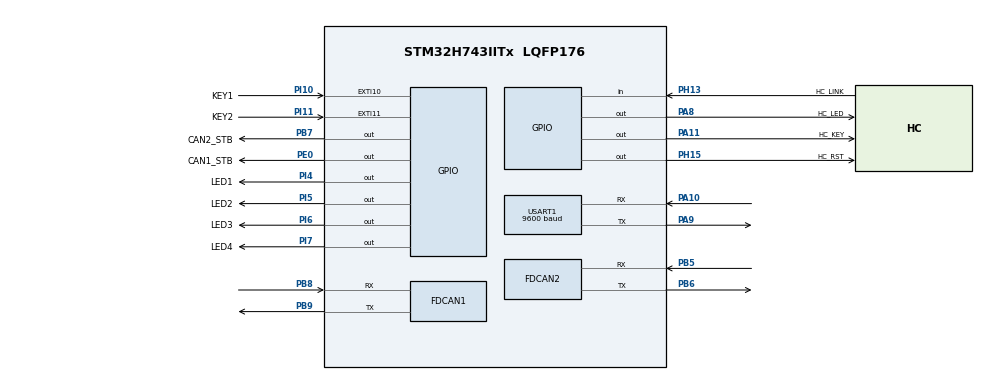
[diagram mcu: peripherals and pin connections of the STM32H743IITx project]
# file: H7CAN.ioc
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FDCAN1.DataSyncJumpWidth=8
FDCAN1.DataTimeSeg1=31
FDCAN1.DataTimeSeg2=8
FDCAN1.NominalSyncJumpWidth=8
FDCAN1.NominalTimeSeg1=31
FDCAN1.NominalTimeSeg2=8
FDCAN2.DataSyncJumpWidth=8
FDCAN2.DataTimeSeg1=31
FDCAN2.DataTimeSeg2=8
FDCAN2.FrameFormat=FDCAN_FRAME_CLASSIC
FDCAN2.NominalPrescaler=1
FDCAN2.NominalSyncJumpWidth=8
FDCAN2.NominalTimeSeg1=31
FDCAN2.NominalTimeSeg2=8
FDCAN2.ProtocolException=ENABLE
FDCAN2.RxBufferSize=FDCAN_DATA_BYTES_8
FDCAN2.RxFifo0ElmtSize=FDCAN_DATA_BYTES_8
FDCAN2.RxFifo0ElmtsNbr=2
FDCAN2.RxFifo1ElmtSize=FDCAN_DATA_BYTES_8
FDCAN2.StdFiltersNbr=1
FDCAN2.TxElmtSize=FDCAN_DATA_BYTES_8
FDCAN2.TxFifoQueueElmtsNbr=1
Mcu.Family=STM32H7
Mcu.Name=STM32H743IITx
Mcu.Package=LQFP176
NVIC.EXTI15_10_IRQn=true\:0\:0\:false\:false\:true\:true\:true
NVIC.PriorityGroup=NVIC_PRIORITYGROUP_4
NVIC.TIM1_UP_IRQn=true\:0\:0\:false\:false\:true\:true\:true
NVIC.USART1_IRQn=true\:0\:0\:false\:false\:true\:true\:true
PA10.GPIO_Speed=GPIO_SPEED_FREQ_VERY_HIGH
PA10.Mode=Asynchronous
PA10.Signal=USART1_RX
PA11.GPIO_Label=HC_KEY
PA11.Signal=GPIO_Output
PA8.GPIO_Label=HC_LED
PA8.Signal=GPIO_Output
PA9.GPIO_Speed=GPIO_SPEED_FREQ_VERY_HIGH
PA9.Mode=Asynchronous
PA9.Signal=USART1_TX
PB5.GPIO_Speed=GPIO_SPEED_FREQ_VERY_HIGH
PB5.Mode=FDCANSlave
PB5.Signal=FDCAN2_RX
PB6.GPIO_FM6=SYSCFG_PMCR_I2C_PB6_FMP
PB6.GPIO_Speed=GPIO_SPEED_FREQ_VERY_HIGH
PB6.Mode=FDCANSlave
PB6.Signal=FDCAN2_TX
PB7.GPIO_Label=CAN2_STB
PB7.GPIO_PuPd=GPIO_PULLDOWN
PB7.Signal=GPIO_Output
PB8.GPIO_FM8=SYSCFG_PMCR_I2C_PB8_FMP
PB8.GPIO_Speed=GPIO_SPEED_FREQ_VERY_HIGH
PB8.Mode=FDCANMaster
PB8.Signal=FDCAN1_RX
PB9.GPIO_FM9=SYSCFG_PMCR_I2C_PB9_FMP
PB9.GPIO_Speed=GPIO_SPEED_FREQ_VERY_HIGH
PB9.Mode=FDCANMaster
PB9.Signal=FDCAN1_TX
PE0.GPIO_Label=CAN1_STB
PE0.Signal=GPIO_Output
PH0-OSC_IN\ (PH0).Mode=HSE-External-Oscillator
PH0-OSC_IN\ (PH0).Signal=RCC_OSC_IN
PH1-OSC_OUT\ (PH1).Mode=HSE-External-Oscillator
PH1-OSC_OUT\ (PH1).Signal=RCC_OSC_OUT
PH13.GPIO_Label=HC_LINK
PH13.Signal=GPIO_Input
PH15.GPIO_Label=HC_RST
PH15.Signal=GPIO_Output
PI10.GPIO_Label=KEY1
PI10.GPIO_PuPd=GPIO_PULLUP
PI10.Signal=GPXTI10
PI11.GPIO_Label=KEY2
PI11.GPIO_PuPd=GPIO_PULLUP
PI11.Signal=GPXTI11
PI4.GPIO_Label=LED1
PI4.Signal=GPIO_Output
PI5.GPIO_Label=LED2
PI5.Signal=GPIO_Output
PI6.GPIO_Label=LED3
PI6.Signal=GPIO_Output
PI7.GPIO_Label=LED4
PI7.Signal=GPIO_Output
ProjectManager.HeapSize=0x200
ProjectManager.StackSize=0x400
ProjectManager.TargetToolchain=MDK-ARM V5
RCC.ADCFreq_Value=50390625
RCC.APB1Freq_Value=50000000
RCC.APB2Freq_Value=50000000
RCC.APB3Freq_Value=50000000
RCC.APB4Freq_Value=50000000
RCC.CortexFreq_Value=200000000
RCC.D1PPRE=RCC_APB3_DIV2
RCC.D2PPRE1=RCC_APB1_DIV2
RCC.D2PPRE2=RCC_APB2_DIV2
RCC.D3PPRE=RCC_APB4_DIV2
RCC.DIVM1=8
RCC.DIVN1=128
RCC.DIVQ1=20
RCC.HCLKFreq_Value=100000000
RCC.HPRE=RCC_HCLK_DIV2
RCC.PLL2FRACN=0
RCC.PLL3FRACN=0
RCC.PLLFRACN=0
RCC.PLLSourceVirtual=RCC_PLLSOURCE_HSE
RCC.SYSCLKFreq_VALUE=200000000
RCC.SYSCLKSource=RCC_SYSCLKSOURCE_PLLCLK
RCC.USBFreq_Value=20000000
TIM1.Period=1000-1
TIM1.Prescaler=19999
USART1.BaudRate=9600
USART1.VirtualMode-Asynchronous=VM_ASYNC
VP_TIM1_VS_ClockSourceINT.Mode=Internal
board=custom

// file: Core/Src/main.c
/* USER CODE BEGIN Header */
/**
  ******************************************************************************
  * @file           : main.c
  * @brief          : Main program body
  ******************************************************************************
  * @attention
  *
  * <h2><center>&copy; Copyright (c) 2019 STMicroelectronics.
  * All rights reserved.</center></h2>
  *
  * This software component is licensed by ST under BSD 3-Clause license,
  * the "License"; You may not use this file except in compliance with the
  * License. You may obtain a copy of the License at:
  *                        opensource.org/licenses/BSD-3-Clause
  *
  ******************************************************************************
  */
/* USER CODE END Header */

#include "main.h"
#include "fdcan.h"
#include "tim.h"
#include "usart.h"
#include "gpio.h"

/* USER CODE BEGIN Includes */
#include "interface.h"
/* USER CODE END Includes */

void SystemClock_Config(void);

int main(void)
{

  /* MCU Configuration--------------------------------------------------------*/

  /* Reset of all peripherals, Initializes the Flash interface and the Systick. */
  HAL_Init();

  /* Configure the system clock */
  SystemClock_Config();

  /* Initialize all configured peripherals */
  MX_GPIO_Init();
  MX_FDCAN2_Init();
  MX_TIM1_Init();
  MX_FDCAN1_Init();
  MX_USART1_UART_Init();
  /* USER CODE BEGIN 2 */

	HardwareInit();
  /* USER CODE END 2 */

  /* Infinite loop */
  /* USER CODE BEGIN WHILE */
  while (1)
  {
		HAL_Delay(300);
		if (PresCANRecvFlg==1)
		{
			BLESend(AllTireInfo);
		}

    /* USER CODE END WHILE */

  }
}

void SystemClock_Config(void)
{
  RCC_OscInitTypeDef RCC_OscInitStruct = {0};
  RCC_ClkInitTypeDef RCC_ClkInitStruct = {0};
  RCC_PeriphCLKInitTypeDef PeriphClkInitStruct = {0};

  /** Supply configuration update enable
  */
  HAL_PWREx_ConfigSupply(PWR_LDO_SUPPLY);
  /** Configure the main internal regulator output voltage
  */
  __HAL_PWR_VOLTAGESCALING_CONFIG(PWR_REGULATOR_VOLTAGE_SCALE3);

  while(!__HAL_PWR_GET_FLAG(PWR_FLAG_VOSRDY)) {}
  /** Initializes the CPU, AHB and APB busses clocks
  */
  RCC_OscInitStruct.OscillatorType = RCC_OSCILLATORTYPE_HSE;
  RCC_OscInitStruct.HSEState = RCC_HSE_ON;
  RCC_OscInitStruct.PLL.PLLState = RCC_PLL_ON;
  RCC_OscInitStruct.PLL.PLLSource = RCC_PLLSOURCE_HSE;
  RCC_OscInitStruct.PLL.PLLM = 8;
  RCC_OscInitStruct.PLL.PLLN = 128;
  RCC_OscInitStruct.PLL.PLLP = 2;
  RCC_OscInitStruct.PLL.PLLQ = 20;
  RCC_OscInitStruct.PLL.PLLR = 2;
  RCC_OscInitStruct.PLL.PLLRGE = RCC_PLL1VCIRANGE_1;
  RCC_OscInitStruct.PLL.PLLVCOSEL = RCC_PLL1VCOWIDE;
  RCC_OscInitStruct.PLL.PLLFRACN = 0;
  if (HAL_RCC_OscConfig(&RCC_OscInitStruct) != HAL_OK)
  {
    Error_Handler();
  }
  /** Initializes the CPU, AHB and APB busses clocks
  */
  RCC_ClkInitStruct.ClockType = RCC_CLOCKTYPE_HCLK|RCC_CLOCKTYPE_SYSCLK
                              |RCC_CLOCKTYPE_PCLK1|RCC_CLOCKTYPE_PCLK2
                              |RCC_CLOCKTYPE_D3PCLK1|RCC_CLOCKTYPE_D1PCLK1;
  RCC_ClkInitStruct.SYSCLKSource = RCC_SYSCLKSOURCE_PLLCLK;
  RCC_ClkInitStruct.SYSCLKDivider = RCC_SYSCLK_DIV1;
  RCC_ClkInitStruct.AHBCLKDivider = RCC_HCLK_DIV2;
  RCC_ClkInitStruct.APB3CLKDivider = RCC_APB3_DIV2;
  RCC_ClkInitStruct.APB1CLKDivider = RCC_APB1_DIV2;
  RCC_ClkInitStruct.APB2CLKDivider = RCC_APB2_DIV2;
  RCC_ClkInitStruct.APB4CLKDivider = RCC_APB4_DIV2;

  if (HAL_RCC_ClockConfig(&RCC_ClkInitStruct, FLASH_LATENCY_1) != HAL_OK)
  {
    Error_Handler();
  }
  PeriphClkInitStruct.PeriphClockSelection = RCC_PERIPHCLK_FDCAN|RCC_PERIPHCLK_USART1;
  PeriphClkInitStruct.FdcanClockSelection = RCC_FDCANCLKSOURCE_PLL;
  PeriphClkInitStruct.Usart16ClockSelection = RCC_USART16CLKSOURCE_D2PCLK2;
  if (HAL_RCCEx_PeriphCLKConfig(&PeriphClkInitStruct) != HAL_OK)
  {
    Error_Handler();
  }
}

void Error_Handler(void)
{
}

/************************ (C) COPYRIGHT STMicroelectronics *****END OF FILE****/
